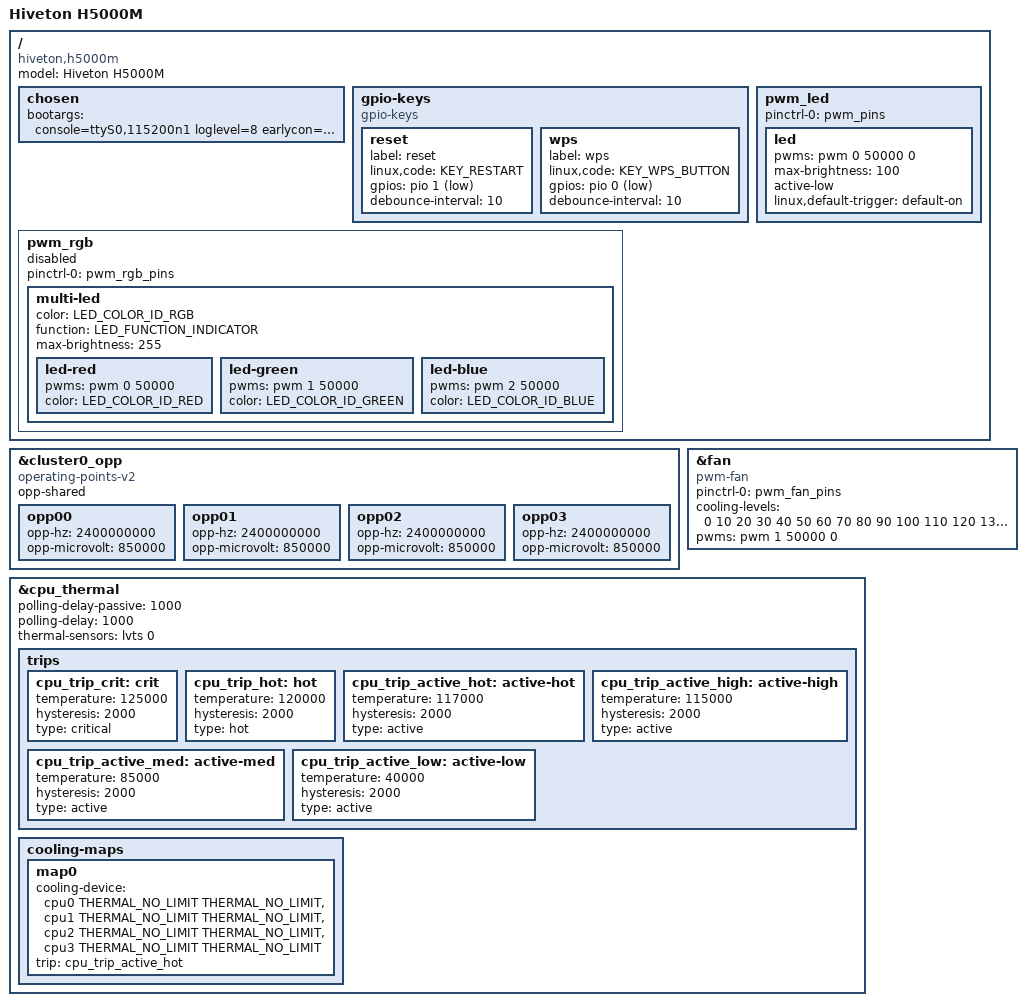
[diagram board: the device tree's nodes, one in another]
// SPDX-License-Identifier: (GPL-2.0 OR MIT)
/*
 * Copyright (C) 2025 MediaTek Inc.
 * Author: Sam.Shih <sam.shih@mediatek.com>
 */

/dts-v1/;
#include "mt7987a.dtsi"
#include <dt-bindings/input/input.h>
#include "mt7987-emmc.dtsi"

/* MT7987A RFB DTS for DT overlay-based device tree */
/ {
	model = "Hiveton H5000M";
	compatible = "hiveton,h5000m", "mediatek,mt7987";

	chosen {
		bootargs = "console=ttyS0,115200n1 loglevel=8  \
                            earlycon=uart8250,mmio32,0x11000000 \
                            pci=pcie_bus_perf \
			    root=PARTLABEL=rootfs rootwait \
			    rootfstype=squashfs,f2fs";
	};

	gpio-keys {
		compatible = "gpio-keys";

		reset {
			label = "reset";
			linux,code = <KEY_RESTART>;
			gpios = <&pio 1 GPIO_ACTIVE_LOW>;
			debounce-interval = <10>;
		};

		wps {
			label = "wps";
			linux,code = <KEY_WPS_BUTTON>;
			gpios = <&pio 0 GPIO_ACTIVE_LOW>;
			debounce-interval = <10>;
		};
	};

	/* use pwm0 as led: share with fan/pwm_rgb */
	pwm_led {
		pinctrl-names = "default";
		pinctrl-0 = <&pwm_pins>;
		status = "okay";

		led {
			pwms = <&pwm 0 50000 0>;
			max-brightness = <100>;
			active-low;
			linux,default-trigger = "default-on";
		};
	};

	/* use pwm0/1/2 as multicolor LED: share with fan/pwm_led */
	pwm_rgb {
		pinctrl-names = "default";
		pinctrl-0 = <&pwm_rgb_pins>;
		status = "disabled";

		multi-led {
			color = <LED_COLOR_ID_RGB>;
			function = LED_FUNCTION_INDICATOR;
			max-brightness = <255>;

			led-red {
				pwms = <&pwm 0 50000>;
				color = <LED_COLOR_ID_RED>;
			};

			led-green {
				pwms = <&pwm 1 50000>;
				color = <LED_COLOR_ID_GREEN>;
			};

			led-blue {
				pwms = <&pwm 2 50000>;
				color = <LED_COLOR_ID_BLUE>;
			};
		};
	};
};

&cluster0_opp {
	compatible = "operating-points-v2";
	opp-shared;
	opp00 {
		opp-hz = /bits/ 64 <2400000000>;
		opp-microvolt = <850000>;
	};
	opp01 {
		opp-hz = /bits/ 64 <2400000000>;
		opp-microvolt = <850000>;
	};
	opp02 {
		opp-hz = /bits/ 64 <2400000000>;
		opp-microvolt = <850000>;
	};
	opp03 {
		opp-hz = /bits/ 64 <2400000000>;
		opp-microvolt = <850000>;
	};
};

&fan {
	pinctrl-names = "default";
	pinctrl-0 = <&pwm_fan_pins>;
	compatible = "pwm-fan";
	#cooling-cells = <2>;
	cooling-levels = <0 10 20 30 40 50 60 70 80 90 100 110 120 130 140 150 160 170 180 190 200 210 220 240 255>;
	pwms = <&pwm 1 50000 0>;
	status = "okay";
};

&cpu_thermal {
	polling-delay-passive = <1000>;
	polling-delay = <1000>;
	thermal-sensors = <&lvts 0>;

	trips {
		cpu_trip_crit: crit {
			temperature = <125000>;
			hysteresis = <2000>;
			type = "critical";
		};

		cpu_trip_hot: hot {
			temperature = <120000>;
			hysteresis = <2000>;
			type = "hot";
		};

		cpu_trip_active_hot: active-hot {
			temperature = <117000>;
			hysteresis = <2000>;
			type = "active";
		};

		cpu_trip_active_high: active-high {
			temperature = <115000>;
			hysteresis = <2000>;
			type = "active";
		};

		cpu_trip_active_med: active-med {
			temperature = <85000>;
			hysteresis = <2000>;
			type = "active";
		};

		cpu_trip_active_low: active-low {
			temperature = <40000>;
			hysteresis = <2000>;
			type = "active";
		};
	};

	cooling-maps {
		map0 {
		/* active: dynamic cpu frequency scaling */
			cooling-device = <&cpu0 THERMAL_NO_LIMIT THERMAL_NO_LIMIT>,
					 <&cpu1 THERMAL_NO_LIMIT THERMAL_NO_LIMIT>,
					 <&cpu2 THERMAL_NO_LIMIT THERMAL_NO_LIMIT>,
					 <&cpu3 THERMAL_NO_LIMIT THERMAL_NO_LIMIT>;
			trip = <&cpu_trip_active_hot>;
		};
	};
};
